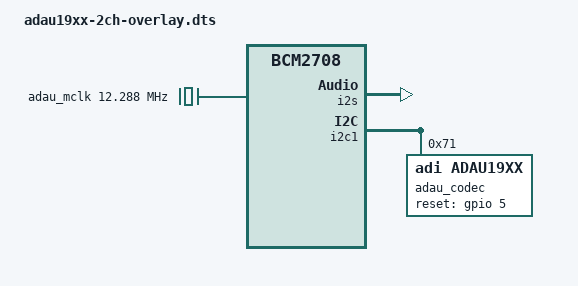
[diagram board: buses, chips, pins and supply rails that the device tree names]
/dts-v1/;
/plugin/;

/ {
    compatible = "brcm,bcm2708";
	fragment@0 {
		target = <&i2s>;
		__overlay__ {
			#sound-dai-cells = <0>;
			status = "okay";
        	};
	};
    fragment@1 {
        target-path = "/clocks";
        __overlay__ {
            adau_mclk: codec-mclk {
                compatible = "fixed-clock";
                #clock-cells = <0>;
                clock-frequency = <12288000>;
            };  
        };
    };
    fragment@2 {
		target = <&i2c1>;
		__overlay__ {
			#address-cells = <1>;
			#size-cells = <0>;
			status = "okay";

			adau_codec: adau1977@71{
				compatible = "adi,adau19xx";
				reg = <0x71>;
				reset-gpios = <&gpio 5 0>;
				#sound-dai-cells = <0>;
				sysclk-src = <1>;//0=SYSCLK_SRC_MCLK 1=SYSCLK_SRC_LRCLK
			};
		};
    };

    fragment@3 {
        target = <&sound>;
        sound_overlay: __overlay__ {
                compatible = "simple-audio-card";
                simple-audio-card,format = "i2s";
                simple-audio-card,name = "adau19xx-card"; 
                status = "okay";
                
                simple-audio-card,bitclock-master = <&dailink0_slave>;
                simple-audio-card,frame-slave = <&dailink0_slave>;               
                dailink0_slave: simple-audio-card,cpu {
                    sound-dai = <&i2s>;
                };
                codec_dai: simple-audio-card,codec {
                    sound-dai = <&adau_codec>;
                    clocks =  <&adau_mclk>;
                };
        };
    };
    __overrides__ {
        card-name = <&sound_overlay>,"adau19xx,name";
    };    

    
};

